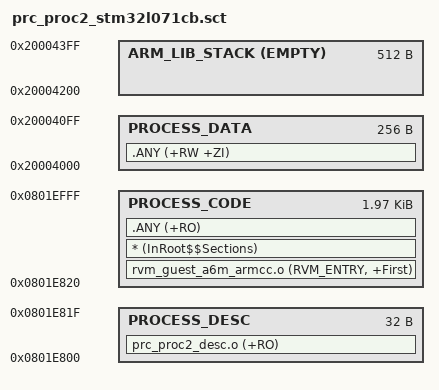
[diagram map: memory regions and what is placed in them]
;******************************************************************************
;Filename    : proc_proc2_stm32l071cb.sct
;Author      : The RVM project generator.
;Date        : 25/08/2024 17:37:30
;Licence     : Unlicense; see COPYING for details.
;Description : The scatter file for ARMv7-M layout. This file is intended
;              to be used with STM32L071CB.
;******************************************************************************

;Descriptor *******************************************************************
DESC 0x801E800 0x20
{
    ;Process header segment
    PROCESS_DESC 0x801E800 0x20
    {
        ;Process header
        prc_proc2_desc.o         (+RO)
    }
}
;End Descriptor ***************************************************************

;Process **********************************************************************
PROCESS 0x801E820 0x7E0
{
    ;Process code segment
    PROCESS_CODE 0x801E820 0x7E0
    {
        ;Entry point assembly
        rvm_guest_a6m_armcc.o     (RVM_ENTRY, +First)
        ;The lib code copying code
        *                      (InRoot$$Sections)
        ;The other code sections
        .ANY                   (+RO)
    }

    ;Process data segment
    PROCESS_DATA 0x20004000 0x100
    {
        .ANY                   (+RW +ZI)
    }

    ;Process stack segment - required by armlib; reusing the booting thread's
    ARM_LIB_STACK 0x20004200 EMPTY 0x200
    {

    }
}
;End Process ******************************************************************

;End Of File ******************************************************************

;Copyright (C) Evo-Devo Instrum. All rights reserved **************************

